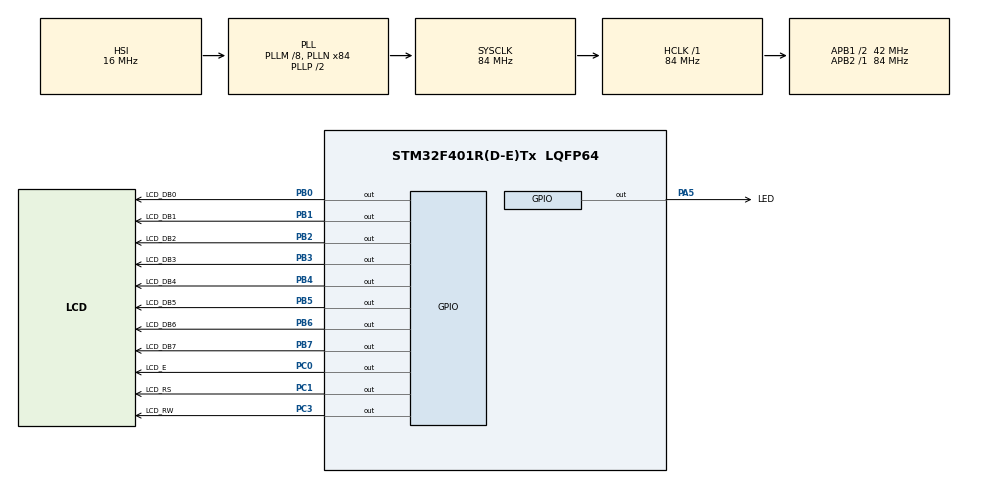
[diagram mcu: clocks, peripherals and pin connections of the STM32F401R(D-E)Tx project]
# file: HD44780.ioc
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Mcu.Family=STM32F4
Mcu.Name=STM32F401R(D-E)Tx
Mcu.Package=LQFP64
NVIC.PriorityGroup=NVIC_PRIORITYGROUP_4
PA5.GPIO_Label=LED
PA5.Signal=GPIO_Output
PB0.GPIO_Label=LCD_DB0
PB0.Signal=GPIO_Output
PB1.GPIO_Label=LCD_DB1
PB1.Signal=GPIO_Output
PB2.GPIO_Label=LCD_DB2
PB2.Signal=GPIO_Output
PB3.GPIO_Label=LCD_DB3
PB3.Signal=GPIO_Output
PB4.GPIO_Label=LCD_DB4
PB4.Signal=GPIO_Output
PB5.GPIO_Label=LCD_DB5
PB5.Signal=GPIO_Output
PB6.GPIO_Label=LCD_DB6
PB6.Signal=GPIO_Output
PB7.GPIO_Label=LCD_DB7
PB7.Signal=GPIO_Output
PC0.GPIO_Label=LCD_E
PC0.Signal=GPIO_Output
PC1.GPIO_Label=LCD_RS
PC1.Signal=GPIO_Output
PC3.GPIO_Label=LCD_RW
PC3.Signal=GPIO_Output
ProjectManager.HeapSize=0x200
ProjectManager.StackSize=0x400
ProjectManager.TargetToolchain=SW4STM32
RCC.48MHZClocksFreq_Value=42000000
RCC.AHBFreq_Value=84000000
RCC.APB1CLKDivider=RCC_HCLK_DIV2
RCC.APB1Freq_Value=42000000
RCC.APB1TimFreq_Value=84000000
RCC.APB2Freq_Value=84000000
RCC.APB2TimFreq_Value=84000000
RCC.CortexFreq_Value=84000000
RCC.HCLKFreq_Value=84000000
RCC.HSE_VALUE=25000000
RCC.HSI_VALUE=16000000
RCC.LSE_VALUE=32768
RCC.PLLM=8
RCC.PLLN=84
RCC.SYSCLKFreq_VALUE=84000000
RCC.SYSCLKSource=RCC_SYSCLKSOURCE_PLLCLK
RCC.VCOOutputFreq_Value=168000000
TIM3.Period=65535
TIM3.Prescaler=83
VP_TIM3_VS_ClockSourceINT.Mode=Internal
board=HD44780

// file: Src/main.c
/**
  ******************************************************************************
  * File Name          : main.c
  * Description        : Main program body
  ******************************************************************************
  ** This notice applies to any and all portions of this file
  * that are not between comment pairs USER CODE BEGIN and
  * USER CODE END. Other portions of this file, whether
  * inserted by the user or by software development tools
  * are owned by their respective copyright owners.
  *
  * COPYRIGHT(c) 2018 STMicroelectronics
  *
  * Redistribution and use in source and binary forms, with or without modification,
  * are permitted provided that the following conditions are met:
  *   1. Redistributions of source code must retain the above copyright notice,
  *      this list of conditions and the following disclaimer.
  *   2. Redistributions in binary form must reproduce the above copyright notice,
  *      this list of conditions and the following disclaimer in the documentation
  *      and/or other materials provided with the distribution.
  *   3. Neither the name of STMicroelectronics nor the names of its contributors
  *      may be used to endorse or promote products derived from this software
  *      without specific prior written permission.
  *
  * THIS SOFTWARE IS PROVIDED BY THE COPYRIGHT HOLDERS AND CONTRIBUTORS "AS IS"
  * AND ANY EXPRESS OR IMPLIED WARRANTIES, INCLUDING, BUT NOT LIMITED TO, THE
  * IMPLIED WARRANTIES OF MERCHANTABILITY AND FITNESS FOR A PARTICULAR PURPOSE ARE
  * DISCLAIMED. IN NO EVENT SHALL THE COPYRIGHT HOLDER OR CONTRIBUTORS BE LIABLE
  * FOR ANY DIRECT, INDIRECT, INCIDENTAL, SPECIAL, EXEMPLARY, OR CONSEQUENTIAL
  * DAMAGES (INCLUDING, BUT NOT LIMITED TO, PROCUREMENT OF SUBSTITUTE GOODS OR
  * SERVICES; LOSS OF USE, DATA, OR PROFITS; OR BUSINESS INTERRUPTION) HOWEVER
  * CAUSED AND ON ANY THEORY OF LIABILITY, WHETHER IN CONTRACT, STRICT LIABILITY,
  * OR TORT (INCLUDING NEGLIGENCE OR OTHERWISE) ARISING IN ANY WAY OUT OF THE USE
  * OF THIS SOFTWARE, EVEN IF ADVISED OF THE POSSIBILITY OF SUCH DAMAGE.
  *
  ******************************************************************************
  */
#include "main.h"
#include "stm32f4xx_hal.h"
#include "tim.h"
#include "gpio.h"

/* USER CODE BEGIN Includes */
#include "LCD_HD44780.h"
/* USER CODE END Includes */

/* USER CODE BEGIN PV */
/* Private variables ---------------------------------------------------------*/

/* USER CODE END PV */

void SystemClock_Config(void);

/* USER CODE BEGIN PFP */
/* Private function prototypes -----------------------------------------------*/

/* USER CODE END PFP */

int main(void)
{

  /* MCU Configuration----------------------------------------------------------*/

  /* Reset of all peripherals, Initializes the Flash interface and the Systick. */
  HAL_Init();

  /* Configure the system clock */
  SystemClock_Config();

  /* Initialize all configured peripherals */
  MX_GPIO_Init();
  MX_TIM3_Init();

  /* USER CODE BEGIN 2 */
  HAL_TIM_Base_Start(&htim3);
  LCD_Init();
  /* USER CODE END 2 */

  /* Infinite loop */
  while (1)
  {

  /* USER CODE BEGIN 3 */
	  // Measurement start
	  LCD_Cls();
	  LCD_Locate(0,0);
	  LCD_String(" STM32 + HD44780");
	  LCD_Locate(0,1);
	  LCD_String("www.msalamon.pl ");
	  // Measurement end
	  HAL_GPIO_TogglePin(LED_GPIO_Port, LED_Pin);
	  HAL_Delay(500);
  }
  /* USER CODE END 3 */

}

/** System Clock Configuration
*/
void SystemClock_Config(void)
{

  RCC_OscInitTypeDef RCC_OscInitStruct;
  RCC_ClkInitTypeDef RCC_ClkInitStruct;

    /**Configure the main internal regulator output voltage
    */
  __HAL_RCC_PWR_CLK_ENABLE();

  __HAL_PWR_VOLTAGESCALING_CONFIG(PWR_REGULATOR_VOLTAGE_SCALE2);

    /**Initializes the CPU, AHB and APB busses clocks
    */
  RCC_OscInitStruct.OscillatorType = RCC_OSCILLATORTYPE_HSI;
  RCC_OscInitStruct.HSIState = RCC_HSI_ON;
  RCC_OscInitStruct.HSICalibrationValue = 16;
  RCC_OscInitStruct.PLL.PLLState = RCC_PLL_ON;
  RCC_OscInitStruct.PLL.PLLSource = RCC_PLLSOURCE_HSI;
  RCC_OscInitStruct.PLL.PLLM = 8;
  RCC_OscInitStruct.PLL.PLLN = 84;
  RCC_OscInitStruct.PLL.PLLP = RCC_PLLP_DIV2;
  RCC_OscInitStruct.PLL.PLLQ = 4;
  if (HAL_RCC_OscConfig(&RCC_OscInitStruct) != HAL_OK)
  {
    _Error_Handler(__FILE__, __LINE__);
  }

    /**Initializes the CPU, AHB and APB busses clocks
    */
  RCC_ClkInitStruct.ClockType = RCC_CLOCKTYPE_HCLK|RCC_CLOCKTYPE_SYSCLK
                              |RCC_CLOCKTYPE_PCLK1|RCC_CLOCKTYPE_PCLK2;
  RCC_ClkInitStruct.SYSCLKSource = RCC_SYSCLKSOURCE_PLLCLK;
  RCC_ClkInitStruct.AHBCLKDivider = RCC_SYSCLK_DIV1;
  RCC_ClkInitStruct.APB1CLKDivider = RCC_HCLK_DIV2;
  RCC_ClkInitStruct.APB2CLKDivider = RCC_HCLK_DIV1;

  if (HAL_RCC_ClockConfig(&RCC_ClkInitStruct, FLASH_LATENCY_2) != HAL_OK)
  {
    _Error_Handler(__FILE__, __LINE__);
  }

    /**Configure the Systick interrupt time
    */
  HAL_SYSTICK_Config(HAL_RCC_GetHCLKFreq()/1000);

    /**Configure the Systick
    */
  HAL_SYSTICK_CLKSourceConfig(SYSTICK_CLKSOURCE_HCLK);

  /* SysTick_IRQn interrupt configuration */
  HAL_NVIC_SetPriority(SysTick_IRQn, 0, 0);
}

void _Error_Handler(char * file, int line)
{
  while(1)
  {
  }
}

/************************ (C) COPYRIGHT STMicroelectronics *****END OF FILE****/
